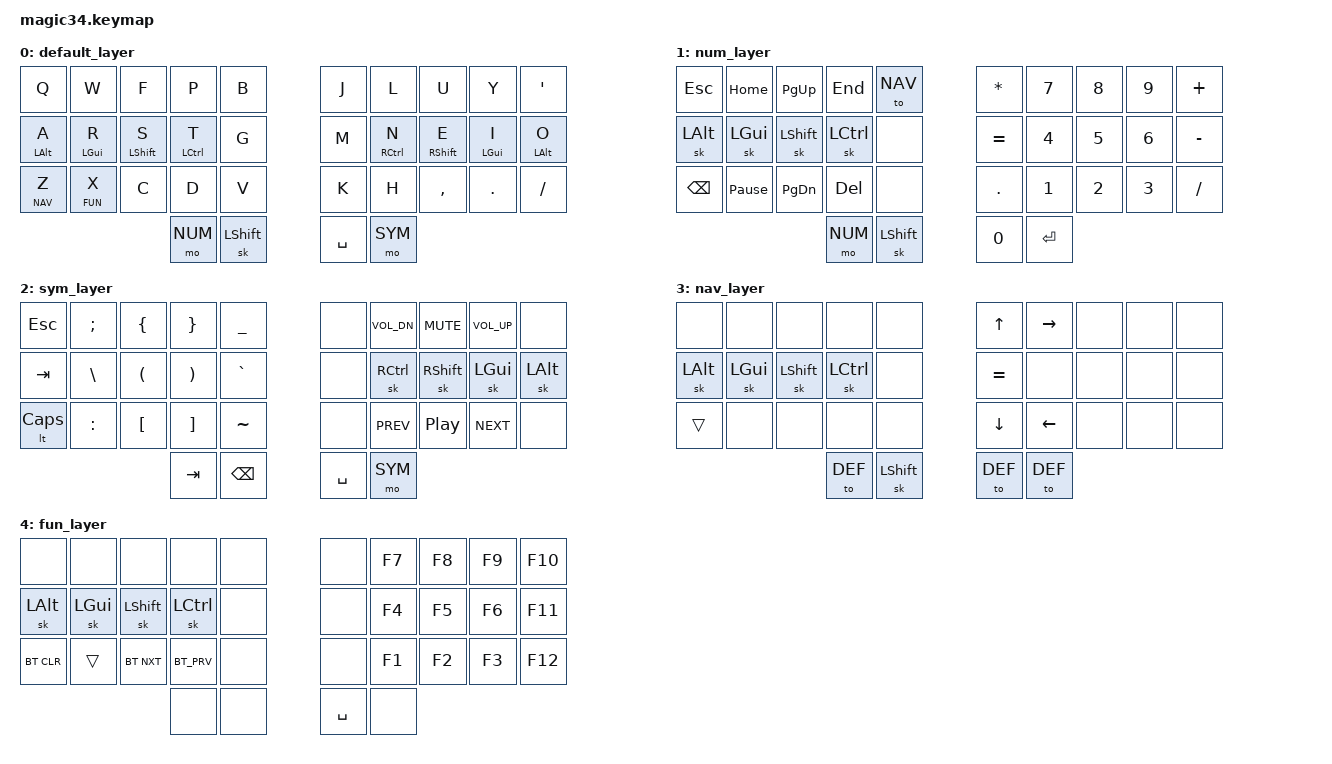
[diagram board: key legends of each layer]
#include <behaviors.dtsi>
#include <dt-bindings/zmk/keys.h>
#include <dt-bindings/zmk/bt.h>

#define DEF   0
#define NUM   1
#define SYM   2
#define NAV   3
#define FUN   4

&sk {
  release-after-ms = <2000>;
  quick-release;
};

/ {
    behaviors {
    hm: homerow_mods {
        compatible = "zmk,behavior-hold-tap";
        label = "HOMEROW_MODS";
        #binding-cells = <2>;
        flavor = "tap-preferred";
        tapping-term-ms = <200>;
        quick_tap_ms = <125>;
        global-quick-tap;
        bindings = <&kp>, <&kp>;
    };
    keymap {
      compatible = "zmk,keymap";

      default_layer {
        bindings = <
          &kp Q        &kp W        &kp F          &kp P        &kp B              &kp J       &kp L        &kp U          &kp Y        &kp SQT
          &hm LALT A   &hm LGUI R   &hm LSHIFT S   &hm LCTL T   &kp G              &kp M       &hm RCTL N   &hm RSHIFT E   &hm LGUI I   &hm LALT O
          &lt NAV Z    &lt FUN X    &kp C          &kp D        &kp V              &kp K       &kp H        &kp COMMA      &kp DOT      &kp FSLH
                                                   &mo NUM      &sk LSHIFT         &kp SPACE   &mo SYM
        >;
      };
      num_layer {
        bindings = <
          &kp ESC    &kp HOME          &kp PG_UP    &kp END     &to NAV            &kp STAR    &kp N7   &kp N8   &kp N9   &kp PLUS
          &sk LALT   &sk LGUI          &sk LSHIFT   &sk LCTL    &none              &kp EQUAL   &kp N4   &kp N5   &kp N6   &kp MINUS
          &kp BSPC   &kp PAUSE_BREAK   &kp PG_DN    &kp DEL     &none              &kp DOT     &kp N1   &kp N2   &kp N3   &kp FSLH
                                                    &mo NUM     &sk LSHIFT         &kp N0      &kp RET
        >;
      };
      sym_layer {
        bindings = <
          &kp ESC    &kp SEMI    &kp LBRC   &kp RBRC   &kp UNDER          &none       &kp C_VOL_DN   &kp C_MUTE   &kp C_VOL_UP   &none
          &kp TAB    &kp BSLH    &kp LPAR   &kp RPAR   &kp GRAVE          &none       &sk RCTL       &sk RSHIFT   &sk LGUI       &sk LALT
          &lt CAPS   &kp COLON   &kp LBKT   &kp RBKT   &kp TILDE          &none       &kp C_PREV     &kp C_PP     &kp C_NEXT     &none
                                            &kp TAB    &kp BSPC           &kp SPACE   &mo SYM
        >;
      };
      nav_layer {
        bindings = <
          &none     &none      &none        &none     &none                 &kp UP      &kp RIGHT   &none   &none   &none
          &sk LALT  &sk LGUI   &sk LSHIFT   &sk LCTL  &none                 &kp EQUAL   &none       &none   &none   &none
          &trans    &none      &none        &none     &none                 &kp DOWN    &kp LEFT    &none   &none   &none
                                            &to DEF   &sk LSHIFT            &to DEF     &to DEF
        >;
      };
      fun_layer {
        bindings = <
          &none        &none      &none        &none        &none              &none       &kp F7   &kp F8   &kp F9   &kp F10
          &sk LALT     &sk LGUI   &sk LSHIFT   &sk LCTL     &none              &none       &kp F4   &kp F5   &kp F6   &kp F11
          &bt BT_CLR   &trans     &bt BT_NXT   &kp BT_PRV   &none              &none       &kp F1   &kp F2   &kp F3   &kp F12
                                               &none        &none              &kp SPACE   &none
        >;
      };
    };
};
